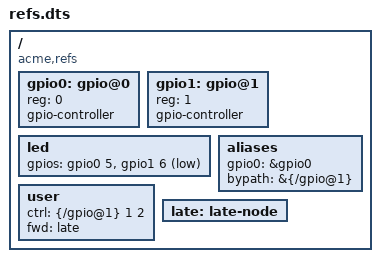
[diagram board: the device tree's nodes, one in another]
/dts-v1/;

/ {
	compatible = "acme,refs";
	#address-cells = <1>;
	#size-cells = <0>;

	gpio0: gpio@0 {
		reg = <0>;
		gpio-controller;
		#gpio-cells = <2>;
	};

	gpio1: gpio@1 {
		reg = <1>;
		gpio-controller;
		#gpio-cells = <2>;
	};

	led {
		gpios = <&gpio0 5 0>, <&gpio1 6 1>;
	};

	aliases {
		gpio0 = &gpio0;
		bypath = &{/gpio@1};
	};

	user {
		ctrl = <&{/gpio@1} 1 2>;
		fwd = <&late>;
	};

	late: late-node {
	};
};
